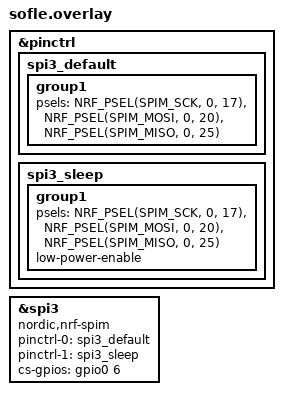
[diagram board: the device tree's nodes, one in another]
/*
 * Copyright (c) 2024 The ZMK Contributors
 *
 * SPDX-License-Identifier: MIT
 */

&pinctrl {
    spi3_default: spi3_default {
        group1 {
            psels = <NRF_PSEL(SPIM_SCK, 0, 17)>,
                    <NRF_PSEL(SPIM_MOSI, 0, 20)>,
                    <NRF_PSEL(SPIM_MISO, 0, 25)>;
        };
    };

    spi3_sleep: spi3_sleep {
        group1 {
            psels = <NRF_PSEL(SPIM_SCK, 0, 17)>,
                    <NRF_PSEL(SPIM_MOSI, 0, 20)>,
                    <NRF_PSEL(SPIM_MISO, 0, 25)>;
            low-power-enable;
        };
    };
};

nice_view_spi: &spi3 {
    status = "okay";
    compatible = "nordic,nrf-spim";
    pinctrl-0 = <&spi3_default>;
    pinctrl-1 = <&spi3_sleep>;
    pinctrl-names = "default", "sleep";
    cs-gpios = <&gpio0 6 GPIO_ACTIVE_HIGH>;
};
